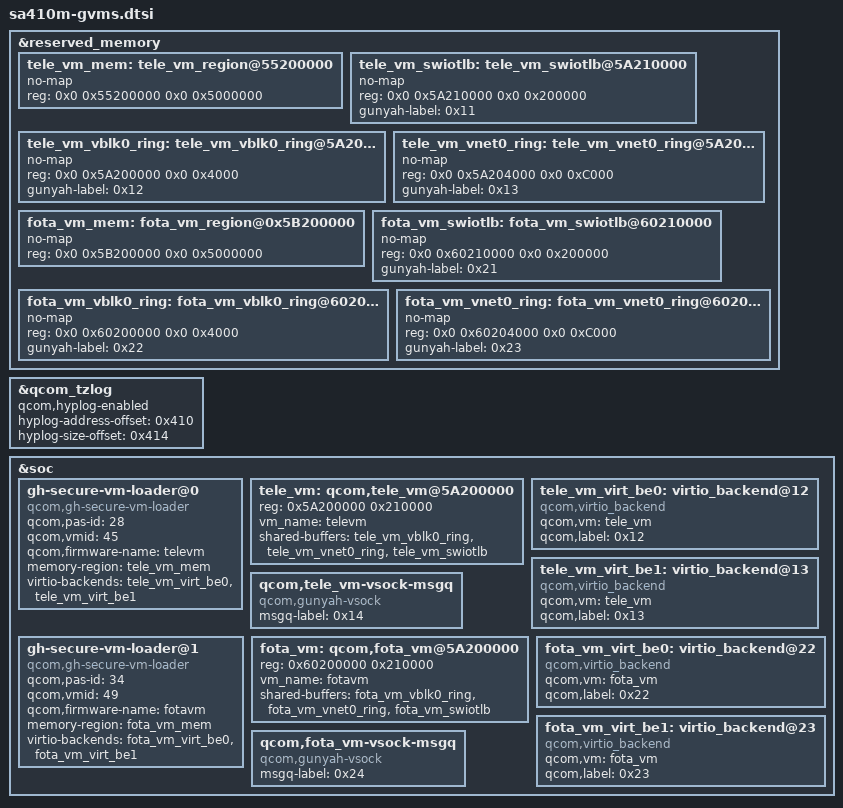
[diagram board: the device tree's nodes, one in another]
// SPDX-License-Identifier: BSD-3-Clause
/*
 * Copyright (c) Qualcomm Technologies, Inc. and/or its subsidiaries.
 */

&reserved_memory {
	tele_vm_mem: tele_vm_region@55200000 {
		no-map;
		reg = <0x0 0x55200000 0x0 0x5000000>;
	};

	tele_vm_swiotlb: tele_vm_swiotlb@5A210000 {
		no-map;
		reg = <0x0 0x5A210000 0x0 0x200000>;
		gunyah-label = <0x11>;
	};

	tele_vm_vblk0_ring: tele_vm_vblk0_ring@5A200000 {
		no-map;
		reg = <0x0 0x5A200000 0x0 0x4000>;
		gunyah-label = <0x12>;
	};

	tele_vm_vnet0_ring: tele_vm_vnet0_ring@5A204000 {
		no-map;
		reg = <0x0 0x5A204000 0x0 0xC000>;
		gunyah-label = <0x13>;
	};

	fota_vm_mem: fota_vm_region@0x5B200000 {
		no-map;
		reg = <0x0 0x5B200000 0x0 0x5000000>;
	};

	fota_vm_swiotlb: fota_vm_swiotlb@60210000 {
		no-map;
		reg = <0x0 0x60210000 0x0 0x200000>;
		gunyah-label = <0x21>;
	};

	fota_vm_vblk0_ring: fota_vm_vblk0_ring@60200000 {
		no-map;
		reg = <0x0 0x60200000 0x0 0x4000>;
		gunyah-label = <0x22>;
	};

	fota_vm_vnet0_ring: fota_vm_vnet0_ring@60204000 {
		no-map;
		reg = <0x0 0x60204000 0x0 0xC000>;
		gunyah-label = <0x23>;
	};

};

&qcom_tzlog {
	qcom,hyplog-enabled;
	hyplog-address-offset = <0x410>;
	hyplog-size-offset = <0x414>;
};

&soc {
	gh-secure-vm-loader@0 {
		compatible = "qcom,gh-secure-vm-loader";
		qcom,pas-id = <28>;
		qcom,vmid = <45>;
		qcom,firmware-name = "televm";
		memory-region = <&tele_vm_mem>;
		virtio-backends = <&tele_vm_virt_be0 &tele_vm_virt_be1>;
	};

	tele_vm: qcom,tele_vm@5A200000 {
		reg = <0x5A200000 0x210000>;
		vm_name = "televm";
		shared-buffers = <&tele_vm_vblk0_ring &tele_vm_vnet0_ring &tele_vm_swiotlb>;
	};

	tele_vm_virt_be0:virtio_backend@12 {
		compatible = "qcom,virtio_backend";
		qcom,vm = <&tele_vm>;
		qcom,label = <0x12>;
	};

	tele_vm_virt_be1:virtio_backend@13 {
		compatible = "qcom,virtio_backend";
		qcom,vm = <&tele_vm>;
		qcom,label = <0x13>;
	};

	qcom,tele_vm-vsock-msgq {
		compatible = "qcom,gunyah-vsock";
		msgq-label = <0x14>;
	};

	gh-secure-vm-loader@1 {
		compatible = "qcom,gh-secure-vm-loader";
		qcom,pas-id = <34>;
		qcom,vmid = <49>;
		qcom,firmware-name = "fotavm";
		memory-region = <&fota_vm_mem>;
		virtio-backends = <&fota_vm_virt_be0 &fota_vm_virt_be1>;
	};

	fota_vm: qcom,fota_vm@5A200000 {
		reg = <0x60200000 0x210000>;
		vm_name = "fotavm";
		shared-buffers = <&fota_vm_vblk0_ring &fota_vm_vnet0_ring &fota_vm_swiotlb>;
	};

	fota_vm_virt_be0:virtio_backend@22 {
		compatible = "qcom,virtio_backend";
		qcom,vm = <&fota_vm>;
		qcom,label = <0x22>;
	};

	fota_vm_virt_be1:virtio_backend@23 {
		compatible = "qcom,virtio_backend";
		qcom,vm = <&fota_vm>;
		qcom,label = <0x23>;
	};

	qcom,fota_vm-vsock-msgq {
		compatible = "qcom,gunyah-vsock";
		msgq-label = <0x24>;
	};

};
